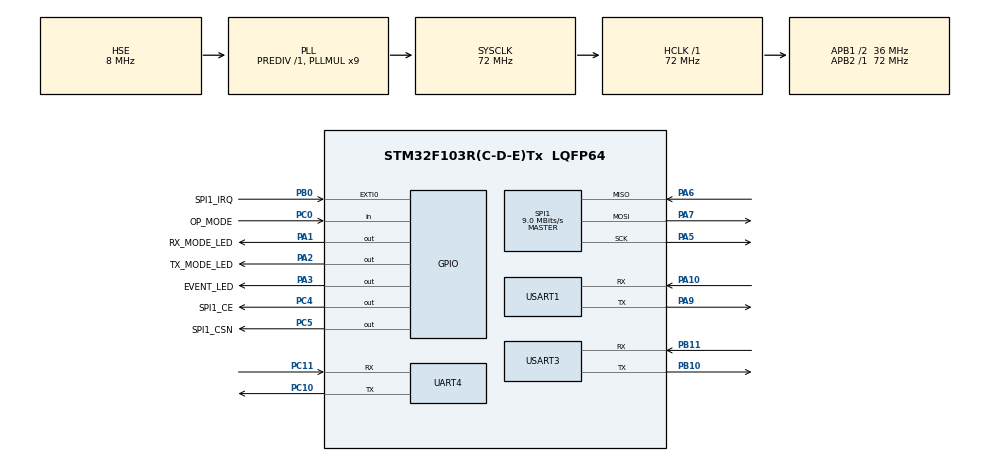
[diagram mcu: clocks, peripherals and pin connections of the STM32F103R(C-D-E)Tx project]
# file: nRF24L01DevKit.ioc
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Mcu.Family=STM32F1
Mcu.Name=STM32F103R(C-D-E)Tx
Mcu.Package=LQFP64
NVIC.EXTI0_IRQn=true\:0\:0\:true\:true\:true\:1\:true\:true\:true
NVIC.PriorityGroup=NVIC_PRIORITYGROUP_4
NVIC.TIM6_IRQn=true\:1\:0\:true\:false\:true\:true\:true\:true
NVIC.TIM7_IRQn=true\:1\:0\:true\:false\:true\:false\:true\:true
NVIC.TimeBase=TIM7_IRQn
NVIC.TimeBaseIP=TIM7
NVIC.UART4_IRQn=true\:3\:0\:true\:false\:true\:true\:true\:true
NVIC.USART1_IRQn=true\:3\:0\:true\:false\:true\:true\:true\:true
NVIC.USART3_IRQn=true\:3\:0\:true\:false\:true\:true\:true\:true
PA1.GPIO_Label=RX_MODE_LED
PA1.Signal=GPIO_Output
PA10.Mode=Asynchronous
PA10.Signal=USART1_RX
PA13.Mode=Serial_Wire
PA13.Signal=SYS_JTMS-SWDIO
PA14.Mode=Serial_Wire
PA14.Signal=SYS_JTCK-SWCLK
PA2.GPIO_Label=TX_MODE_LED
PA2.Signal=GPIO_Output
PA3.GPIO_Label=EVENT_LED
PA3.Signal=GPIO_Output
PA5.Mode=Full_Duplex_Master
PA5.Signal=SPI1_SCK
PA6.Mode=Full_Duplex_Master
PA6.Signal=SPI1_MISO
PA7.Mode=Full_Duplex_Master
PA7.Signal=SPI1_MOSI
PA9.Mode=Asynchronous
PA9.Signal=USART1_TX
PB0.GPIO_Label=SPI1_IRQ
PB0.GPIO_ModeDefaultEXTI=GPIO_MODE_IT_FALLING
PB0.Signal=GPXTI0
PB10.Mode=Asynchronous
PB10.Signal=USART3_TX
PB11.Mode=Asynchronous
PB11.Signal=USART3_RX
PC0.GPIO_Label=OP_MODE
PC0.Signal=GPIO_Input
PC10.Mode=Asynchronous
PC10.Signal=UART4_TX
PC11.Mode=Asynchronous
PC11.Signal=UART4_RX
PC4.GPIO_Label=SPI1_CE
PC4.GPIO_Speed=GPIO_SPEED_FREQ_HIGH
PC4.PinState=GPIO_PIN_RESET
PC4.Signal=GPIO_Output
PC5.GPIO_Label=SPI1_CSN
PC5.GPIO_Speed=GPIO_SPEED_FREQ_HIGH
PC5.PinState=GPIO_PIN_SET
PC5.Signal=GPIO_Output
PD0-OSC_IN.Mode=HSE-External-Oscillator
PD0-OSC_IN.Signal=RCC_OSC_IN
PD1-OSC_OUT.Mode=HSE-External-Oscillator
PD1-OSC_OUT.Signal=RCC_OSC_OUT
ProjectManager.HeapSize=0x200
ProjectManager.StackSize=0x400
ProjectManager.TargetToolchain=STM32CubeIDE
RCC.AHBFreq_Value=72000000
RCC.APB1CLKDivider=RCC_HCLK_DIV2
RCC.APB1Freq_Value=36000000
RCC.APB1TimFreq_Value=72000000
RCC.APB2Freq_Value=72000000
RCC.APB2TimFreq_Value=72000000
RCC.HCLKFreq_Value=72000000
RCC.PLLMUL=RCC_PLL_MUL9
RCC.PLLSourceVirtual=RCC_PLLSOURCE_HSE
RCC.SYSCLKFreq_VALUE=72000000
RCC.SYSCLKSource=RCC_SYSCLKSOURCE_PLLCLK
RCC.USBFreq_Value=72000000
SPI1.BaudRatePrescaler=SPI_BAUDRATEPRESCALER_8
SPI1.CLKPhase=SPI_PHASE_1EDGE
SPI1.CLKPolarity=SPI_POLARITY_LOW
SPI1.CalculateBaudRate=9.0 MBits/s
SPI1.Direction=SPI_DIRECTION_2LINES
SPI1.Mode=SPI_MODE_MASTER
SPI1.VirtualType=VM_MASTER
TIM6.AutoReloadPreload=TIM_AUTORELOAD_PRELOAD_ENABLE
TIM6.Period=100-1
TIM6.Prescaler=720-1
UART4.VirtualMode=Asynchronous
USART1.VirtualMode=VM_ASYNC
USART3.VirtualMode=VM_ASYNC
VP_SYS_VS_tim7.Mode=TIM7
VP_TIM6_VS_ClockSourceINT.Mode=Enable_Timer
board=custom

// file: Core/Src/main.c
/* USER CODE BEGIN Header */
/**
  ******************************************************************************
  * @file           : main.c
  * @brief          : Main program body
  ******************************************************************************
  * @attention
  *
  * Copyright (c) 2025 STMicroelectronics.
  * All rights reserved.
  *
  * This software is licensed under terms that can be found in the LICENSE file
  * in the root directory of this software component.
  * If no LICENSE file comes with this software, it is provided AS-IS.
  *
  ******************************************************************************
  */
/* USER CODE END Header */
#include "main.h"

/* USER CODE BEGIN Includes */
#include "mainProc.h"
/* USER CODE END Includes */

SPI_HandleTypeDef hspi1;

TIM_HandleTypeDef htim6;

UART_HandleTypeDef huart4;
UART_HandleTypeDef huart1;
UART_HandleTypeDef huart3;

void SystemClock_Config(void);
static void MX_GPIO_Init(void);
static void MX_USART1_UART_Init(void);
static void MX_USART3_UART_Init(void);
static void MX_SPI1_Init(void);
static void MX_TIM6_Init(void);
static void MX_UART4_Init(void);
static void MX_NVIC_Init(void);

int main(void)
{

  /* MCU Configuration--------------------------------------------------------*/

  /* Reset of all peripherals, Initializes the Flash interface and the Systick. */
  HAL_Init();

  /* Configure the system clock */
  SystemClock_Config();

  /* Initialize all configured peripherals */
  MX_GPIO_Init();
  MX_USART1_UART_Init();
  MX_USART3_UART_Init();
  MX_SPI1_Init();
  MX_TIM6_Init();
  MX_UART4_Init();

  /* Initialize interrupts */
  MX_NVIC_Init();
  /* USER CODE BEGIN 2 */
  MainProc() ;
#if 0
  /* USER CODE END 2 */

  /* Infinite loop */
  while (1)
  {

    /* USER CODE BEGIN 3 */
  }
#endif
  /* USER CODE END 3 */
}

void SystemClock_Config(void)
{
  RCC_OscInitTypeDef RCC_OscInitStruct = {0};
  RCC_ClkInitTypeDef RCC_ClkInitStruct = {0};

  /** Initializes the RCC Oscillators according to the specified parameters
  * in the RCC_OscInitTypeDef structure.
  */
  RCC_OscInitStruct.OscillatorType = RCC_OSCILLATORTYPE_HSE;
  RCC_OscInitStruct.HSEState = RCC_HSE_ON;
  RCC_OscInitStruct.HSEPredivValue = RCC_HSE_PREDIV_DIV1;
  RCC_OscInitStruct.HSIState = RCC_HSI_ON;
  RCC_OscInitStruct.PLL.PLLState = RCC_PLL_ON;
  RCC_OscInitStruct.PLL.PLLSource = RCC_PLLSOURCE_HSE;
  RCC_OscInitStruct.PLL.PLLMUL = RCC_PLL_MUL9;
  if (HAL_RCC_OscConfig(&RCC_OscInitStruct) != HAL_OK)
  {
    Error_Handler();
  }

  /** Initializes the CPU, AHB and APB buses clocks
  */
  RCC_ClkInitStruct.ClockType = RCC_CLOCKTYPE_HCLK|RCC_CLOCKTYPE_SYSCLK
                              |RCC_CLOCKTYPE_PCLK1|RCC_CLOCKTYPE_PCLK2;
  RCC_ClkInitStruct.SYSCLKSource = RCC_SYSCLKSOURCE_PLLCLK;
  RCC_ClkInitStruct.AHBCLKDivider = RCC_SYSCLK_DIV1;
  RCC_ClkInitStruct.APB1CLKDivider = RCC_HCLK_DIV2;
  RCC_ClkInitStruct.APB2CLKDivider = RCC_HCLK_DIV1;

  if (HAL_RCC_ClockConfig(&RCC_ClkInitStruct, FLASH_LATENCY_2) != HAL_OK)
  {
    Error_Handler();
  }
}

/**
  * @brief NVIC Configuration.
  * @retval None
  */
static void MX_NVIC_Init(void)
{
  /* EXTI0_IRQn interrupt configuration */
  HAL_NVIC_SetPriority(EXTI0_IRQn, 0, 0);
  HAL_NVIC_EnableIRQ(EXTI0_IRQn);
}

static void MX_SPI1_Init(void)
{

  /* SPI1 parameter configuration*/
  hspi1.Instance = SPI1;
  hspi1.Init.Mode = SPI_MODE_MASTER;
  hspi1.Init.Direction = SPI_DIRECTION_2LINES;
  hspi1.Init.DataSize = SPI_DATASIZE_8BIT;
  hspi1.Init.CLKPolarity = SPI_POLARITY_LOW;
  hspi1.Init.CLKPhase = SPI_PHASE_1EDGE;
  hspi1.Init.NSS = SPI_NSS_SOFT;
  hspi1.Init.BaudRatePrescaler = SPI_BAUDRATEPRESCALER_8;
  hspi1.Init.FirstBit = SPI_FIRSTBIT_MSB;
  hspi1.Init.TIMode = SPI_TIMODE_DISABLE;
  hspi1.Init.CRCCalculation = SPI_CRCCALCULATION_DISABLE;
  hspi1.Init.CRCPolynomial = 10;
  if (HAL_SPI_Init(&hspi1) != HAL_OK)
  {
    Error_Handler();
  }

}

static void MX_TIM6_Init(void)
{

  TIM_MasterConfigTypeDef sMasterConfig = {0};

  htim6.Instance = TIM6;
  htim6.Init.Prescaler = 720-1;
  htim6.Init.CounterMode = TIM_COUNTERMODE_UP;
  htim6.Init.Period = 100-1;
  htim6.Init.AutoReloadPreload = TIM_AUTORELOAD_PRELOAD_ENABLE;
  if (HAL_TIM_Base_Init(&htim6) != HAL_OK)
  {
    Error_Handler();
  }
  sMasterConfig.MasterOutputTrigger = TIM_TRGO_RESET;
  sMasterConfig.MasterSlaveMode = TIM_MASTERSLAVEMODE_DISABLE;
  if (HAL_TIMEx_MasterConfigSynchronization(&htim6, &sMasterConfig) != HAL_OK)
  {
    Error_Handler();
  }

}

static void MX_UART4_Init(void)
{

  huart4.Instance = UART4;
  huart4.Init.BaudRate = 115200;
  huart4.Init.WordLength = UART_WORDLENGTH_8B;
  huart4.Init.StopBits = UART_STOPBITS_1;
  huart4.Init.Parity = UART_PARITY_NONE;
  huart4.Init.Mode = UART_MODE_TX_RX;
  huart4.Init.HwFlowCtl = UART_HWCONTROL_NONE;
  huart4.Init.OverSampling = UART_OVERSAMPLING_16;
  if (HAL_UART_Init(&huart4) != HAL_OK)
  {
    Error_Handler();
  }

}

static void MX_USART1_UART_Init(void)
{

  huart1.Instance = USART1;
  huart1.Init.BaudRate = 115200;
  huart1.Init.WordLength = UART_WORDLENGTH_8B;
  huart1.Init.StopBits = UART_STOPBITS_1;
  huart1.Init.Parity = UART_PARITY_NONE;
  huart1.Init.Mode = UART_MODE_TX_RX;
  huart1.Init.HwFlowCtl = UART_HWCONTROL_NONE;
  huart1.Init.OverSampling = UART_OVERSAMPLING_16;
  if (HAL_UART_Init(&huart1) != HAL_OK)
  {
    Error_Handler();
  }

}

static void MX_USART3_UART_Init(void)
{

  huart3.Instance = USART3;
  huart3.Init.BaudRate = 115200;
  huart3.Init.WordLength = UART_WORDLENGTH_8B;
  huart3.Init.StopBits = UART_STOPBITS_1;
  huart3.Init.Parity = UART_PARITY_NONE;
  huart3.Init.Mode = UART_MODE_TX_RX;
  huart3.Init.HwFlowCtl = UART_HWCONTROL_NONE;
  huart3.Init.OverSampling = UART_OVERSAMPLING_16;
  if (HAL_UART_Init(&huart3) != HAL_OK)
  {
    Error_Handler();
  }

}

static void MX_GPIO_Init(void)
{
  GPIO_InitTypeDef GPIO_InitStruct = {0};

  /* GPIO Ports Clock Enable */
  __HAL_RCC_GPIOD_CLK_ENABLE();
  __HAL_RCC_GPIOC_CLK_ENABLE();
  __HAL_RCC_GPIOA_CLK_ENABLE();
  __HAL_RCC_GPIOB_CLK_ENABLE();

  /*Configure GPIO pin Output Level */
  HAL_GPIO_WritePin(GPIOA, RX_MODE_LED_Pin|TX_MODE_LED_Pin|EVENT_LED_Pin, GPIO_PIN_RESET);

  /*Configure GPIO pin Output Level */
  HAL_GPIO_WritePin(SPI1_CE_GPIO_Port, SPI1_CE_Pin, GPIO_PIN_RESET);

  /*Configure GPIO pin Output Level */
  HAL_GPIO_WritePin(SPI1_CSN_GPIO_Port, SPI1_CSN_Pin, GPIO_PIN_SET);

  /*Configure GPIO pin : OP_MODE_Pin */
  GPIO_InitStruct.Pin = OP_MODE_Pin;
  GPIO_InitStruct.Mode = GPIO_MODE_INPUT;
  GPIO_InitStruct.Pull = GPIO_NOPULL;
  HAL_GPIO_Init(OP_MODE_GPIO_Port, &GPIO_InitStruct);

  /*Configure GPIO pins : RX_MODE_LED_Pin TX_MODE_LED_Pin EVENT_LED_Pin */
  GPIO_InitStruct.Pin = RX_MODE_LED_Pin|TX_MODE_LED_Pin|EVENT_LED_Pin;
  GPIO_InitStruct.Mode = GPIO_MODE_OUTPUT_PP;
  GPIO_InitStruct.Pull = GPIO_NOPULL;
  GPIO_InitStruct.Speed = GPIO_SPEED_FREQ_LOW;
  HAL_GPIO_Init(GPIOA, &GPIO_InitStruct);

  /*Configure GPIO pins : SPI1_CE_Pin SPI1_CSN_Pin */
  GPIO_InitStruct.Pin = SPI1_CE_Pin|SPI1_CSN_Pin;
  GPIO_InitStruct.Mode = GPIO_MODE_OUTPUT_PP;
  GPIO_InitStruct.Pull = GPIO_NOPULL;
  GPIO_InitStruct.Speed = GPIO_SPEED_FREQ_HIGH;
  HAL_GPIO_Init(GPIOC, &GPIO_InitStruct);

  /*Configure GPIO pin : SPI1_IRQ_Pin */
  GPIO_InitStruct.Pin = SPI1_IRQ_Pin;
  GPIO_InitStruct.Mode = GPIO_MODE_IT_FALLING;
  GPIO_InitStruct.Pull = GPIO_NOPULL;
  HAL_GPIO_Init(SPI1_IRQ_GPIO_Port, &GPIO_InitStruct);

}

void HAL_TIM_PeriodElapsedCallback(TIM_HandleTypeDef *htim)
{
  if (htim->Instance == TIM7)
  {
    HAL_IncTick();
  }
  /* USER CODE BEGIN Callback 1 */
  if( htim->Instance == TIM6 )
  {
	  TimIrq() ;
  }

  /* USER CODE END Callback 1 */
}

void Error_Handler(void)
{
  __disable_irq();
  while (1)
  {
  }
}
